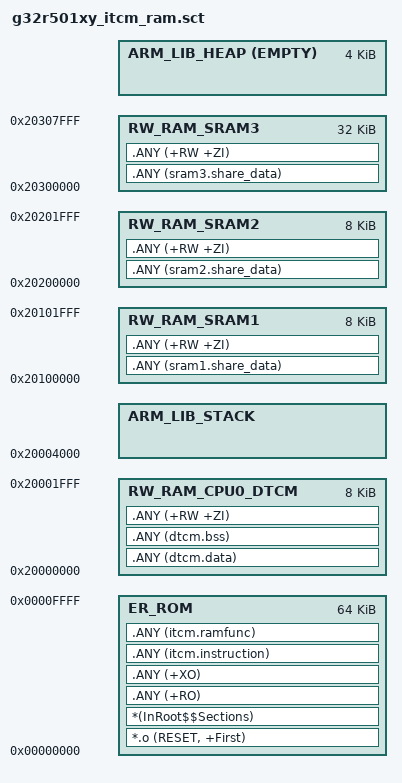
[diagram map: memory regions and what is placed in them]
#! armclang -E --target=arm-arm-none-eabi -mcpu=cortex-m52 -xc
; command above MUST be in first line (no comment above!)

/*
;-------- <<< Use Configuration Wizard in Context Menu >>> -------------------
*/

// Define the size of ITCM and DTCM RAM for CPU0
#define __CPU0_ITCM_BASE              0x00000000
#define __CPU0_ITCM_SIZE              0x00010000   // 64KB
#define __CPU0_DTCM_BASE              0x20000000
#define __CPU0_DTCM_SIZE              0x00004000   // 16KB

// Define the size of CBUS and ITCM Flash for CPU0
#define __CPU0_CBUS_FLASH_BASE        0x08000000
#define __CPU0_CBUS_FLASH_SIZE        0x000A0000   // 640KB
#define __CPU0_ITCM_FLASH_BASE        0x0
#define __CPU0_ITCM_FLASH_SIZE        0x0

#define __CPU0_ROM_BASE               __CPU0_CBUS_FLASH_BASE
#define __CPU0_ROM_SIZE               __CPU0_CBUS_FLASH_SIZE


/*--------------------- SRAM Configuration ----------------------------------
; <h> SRAM Configuration
;   <e0> Enable SRAM1
;     <i> Note: Enabling this option will configure SRAM1 for use.
;     <o1> SRAM1 Base Address <0x20000000-0x2001FFFF:8>
;     <o2> SRAM1 Size (in Bytes) <0x0-0x2000:8>
;     <i> Note: In dual-core MCUs, you need to consider that the SRAM1 ranges used by different cores cannot be the same!
;   </e>
;
;   <e4> Enable SRAM2
;     <i> Note: Enabling this option will configure SRAM2 for use.
;     <o5> SRAM2 Base Address <0x20020000-0x2003FFFF:8>
;     <o6> SRAM2 Size (in Bytes) <0x0-0x2000:8>
;     <i> Note: In dual-core MCUs, you need to consider that the SRAM2 ranges used by different cores cannot be the same!
;   </e>
;
;   <e8> Enable SRAM3
;     <i> Note: Enabling this option will configure SRAM3 for use.
;     <o9> SRAM3 Base Address <0x20040000-0x2007FFFF:8>
;     <o10> SRAM3 Size (in Bytes) <0x0-0x8000:8>
;     <i> Note: In dual-core MCUs, you need to consider that the SRAM3 ranges used by different cores cannot be the same!
;   </e>
; </h>
 *----------------------------------------------------------------------------*/
#define __SRAM1_ENABLED     1
#define __SRAM1_BASE        0x20100000
#define __SRAM1_SIZE        0x00002000   // __SRAM1_SIZE,8KB

#define __SRAM2_ENABLED     1
#define __SRAM2_BASE        0x20200000
#define __SRAM2_SIZE        0x00002000   // __SRAM2_SIZE,8KB

#define __SRAM3_ENABLED     1
#define __SRAM3_BASE        0x20300000
#define __SRAM3_SIZE        0x00008000   // __SRAM3_SIZE,32KB

/*--------------------- Stack / Heap Configuration ---------------------------
; <h> Stack / Heap Configuration
;   <o0> Stack Size (in Bytes) <0x0-0xFFFFFFFF:8>
;   <o1> Heap Size (in Bytes) <0x0-0xFFFFFFFF:8>
;   <o2> Stack Top Location
;      <0=> DTCM (Default)
;      <1=> SRAM1
;      <2=> SRAM2
;      <3=> SRAM3
;   <i> Note: The default stack location is in the chip's DTCM. DMA accessed data should not be placed here. 
;   <i> It should be placed in a separate section such as dma_data, or you can choose to place the stack in other locations.
; </h>
 *----------------------------------------------------------------------------*/
#define __STACK_SIZE       0x00001000
#define __HEAP_SIZE        0x00001000
#define __STACK_TOP_LOCATION 0

#if __STACK_TOP_LOCATION == 0
    #define __STACK_TOP    (__CPU0_DTCM_BASE + __CPU0_DTCM_SIZE)  /* Default: starts at end of DTCM0 */
#elif __STACK_TOP_LOCATION == 1
    #define __STACK_TOP    (__SRAM1_BASE + __SRAM1_SIZE)          /* starts at end of SRAM1 */
#elif __STACK_TOP_LOCATION == 2
    #define __STACK_TOP    (__SRAM2_BASE + __SRAM2_SIZE)          /* starts at end of SRAM2 */
#elif __STACK_TOP_LOCATION == 3
    #define __STACK_TOP    (__SRAM3_BASE + __SRAM3_SIZE)          /* starts at end of SRAM3 */
#else
    #error "Invalid STACK_TOP_LOCATION!"
#endif

#define __HEAP_BASE        (AlignExpr((__STACK_TOP - __STACK_SIZE - __HEAP_SIZE), 8))

/*--------------------- Code Execution Region Configuration ------------------
; <h> Code Execution Region Configuration
;   <o> Code Execution Region
;      <0=> Flash (Default)
;      <1=> SRAM1
;      <2=> SRAM2
;      <3=> SRAM3
;      <4=> ITCM
;      <5=> DTCM
;      <6=> Custom Address
;   <i> Note: In dual-core MCUs, you need to consider that the ROM ranges used by different cores cannot be the same!
 *----------------------------------------------------------------------------*/
#define __CODE_EXEC_REGION  4

#if __CODE_EXEC_REGION == 0
    #define __RO_BASE    __CPU0_ROM_BASE
    #define __RO_SIZE    __CPU0_ROM_SIZE
#elif __CODE_EXEC_REGION == 1
    #define __RO_BASE    __SRAM1_BASE
    #define __RO_SIZE    __SRAM1_SIZE
#elif __CODE_EXEC_REGION == 2
    #define __RO_BASE    __SRAM2_BASE
    #define __RO_SIZE    __SRAM2_SIZE
#elif __CODE_EXEC_REGION == 3
    #define __RO_BASE    __SRAM3_BASE
    #define __RO_SIZE    __SRAM3_SIZE
#elif __CODE_EXEC_REGION == 4
    #define __RO_BASE    __CPU0_ITCM_BASE
    #define __RO_SIZE    __CPU0_ITCM_SIZE
#elif __CODE_EXEC_REGION == 5
    #define __RO_BASE    __CPU0_DTCM_BASE
    #define __RO_SIZE    __CPU0_DTCM_SIZE
#elif __CODE_EXEC_REGION == 6
    /*--------------------- Custom Address Configuration ---------------------
    ; <h> Custom Address Configuration
    ; <i> Note1: Only edit these settings if "Code Execution Region" is set to "Custom Address (6)"
    ; <i> Note2: In dual-core MCUs, you need to consider that the ROM ranges used by different cores cannot be the same!
    ;   <o0> Custom Base Address <0x0-0xFFFFFFFF:8>
    ;   <i> Note 1: Only edit these settings if "Code Execution Region" is set to "Custom Address (6)"
    ;   <i> Note 2: In dual-core MCUs, you need to consider that the ROM ranges used by different cores cannot be the same!
    ;   <o1> Custom Size (in Bytes) <0x0-0xFFFFFFFF:8>
    ;   <i> Note 1: Only edit these settings if "Code Execution Region" is set to "Custom Address (6)"
    ;   <i> Note 2: In dual-core MCUs, you need to consider that the ROM ranges used by different cores cannot be the same!
    ; </h>
     *------------------------------------------------------------------------*/
    #define __CUSTOM_BASE  0x08000000 // Default custom base address
    #define __CUSTOM_SIZE  0x000A0000 // Default custom size
    #define __RO_BASE      __CUSTOM_BASE
    #define __RO_SIZE      __CUSTOM_SIZE
#endif

LR_ROM __RO_BASE __RO_SIZE {                       ; load region size_region
  ER_ROM __RO_BASE __RO_SIZE {                     ; load address = execution address
   *.o (RESET, +First)
   *(InRoot$$Sections)
   .ANY (+RO)
   .ANY (+XO)
#if __CODE_EXEC_REGION == 4
    .ANY (itcm.instruction)
    .ANY (itcm.ramfunc)
#endif
  }

#if __CODE_EXEC_REGION != 4
  RW_RAM_CPU0_ITCM __CPU0_ITCM_BASE __CPU0_ITCM_SIZE {
    .ANY (itcm.instruction)
    .ANY (itcm.ramfunc)
    .ANY (+RW +ZI)
  }
#endif

#if __STACK_TOP_LOCATION == 0
  RW_RAM_CPU0_DTCM __CPU0_DTCM_BASE __CPU0_DTCM_SIZE - __STACK_SIZE - __HEAP_SIZE {
#else
  RW_RAM_CPU0_DTCM __CPU0_DTCM_BASE __CPU0_DTCM_SIZE {
#endif
    .ANY (dtcm.data)
    .ANY (dtcm.bss)
    .ANY (+RW +ZI)
  }

#if __SRAM1_ENABLED
#if __STACK_TOP_LOCATION == 1
  RW_RAM_SRAM1 __SRAM1_BASE __SRAM1_SIZE - __STACK_SIZE - __HEAP_SIZE {
#else
  RW_RAM_SRAM1 __SRAM1_BASE __SRAM1_SIZE {
#endif
    .ANY (sram1.share_data)
    .ANY (+RW +ZI)
  }
#endif

#if __SRAM2_ENABLED
#if __STACK_TOP_LOCATION == 2
  RW_RAM_SRAM2 __SRAM2_BASE __SRAM2_SIZE - __STACK_SIZE - __HEAP_SIZE {
#else
  RW_RAM_SRAM2 __SRAM2_BASE __SRAM2_SIZE {
#endif
    .ANY (sram2.share_data)
    .ANY (+RW +ZI)
  }
#endif

#if __SRAM3_ENABLED
#if __STACK_TOP_LOCATION == 3
  RW_RAM_SRAM3 __SRAM3_BASE __SRAM3_SIZE - __STACK_SIZE - __HEAP_SIZE {
#else
  RW_RAM_SRAM3 __SRAM3_BASE __SRAM3_SIZE {
#endif
    .ANY (sram3.share_data)
    .ANY (+RW +ZI)
  }
#endif

#if __HEAP_SIZE > 0
  ARM_LIB_HEAP __HEAP_BASE EMPTY __HEAP_SIZE {   ; Reserve empty region for heap
  }
#endif

  ARM_LIB_STACK __STACK_TOP EMPTY - __STACK_SIZE {   ; Reserve empty region for stack
  }
}
